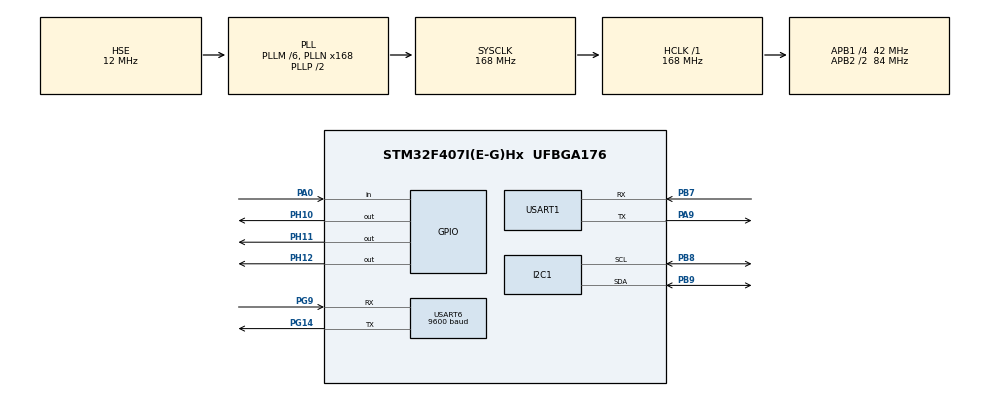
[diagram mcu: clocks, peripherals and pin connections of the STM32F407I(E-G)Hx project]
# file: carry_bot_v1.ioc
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Dma.I2C1_RX.4.Direction=DMA_PERIPH_TO_MEMORY
Dma.I2C1_RX.4.FIFOMode=DMA_FIFOMODE_DISABLE
Dma.I2C1_RX.4.Instance=DMA1_Stream0
Dma.I2C1_RX.4.MemDataAlignment=DMA_MDATAALIGN_BYTE
Dma.I2C1_RX.4.MemInc=DMA_MINC_ENABLE
Dma.I2C1_RX.4.Mode=DMA_NORMAL
Dma.I2C1_RX.4.PeriphDataAlignment=DMA_PDATAALIGN_BYTE
Dma.I2C1_RX.4.PeriphInc=DMA_PINC_DISABLE
Dma.I2C1_RX.4.Priority=DMA_PRIORITY_LOW
Dma.I2C1_TX.5.Direction=DMA_MEMORY_TO_PERIPH
Dma.I2C1_TX.5.FIFOMode=DMA_FIFOMODE_DISABLE
Dma.I2C1_TX.5.Instance=DMA1_Stream6
Dma.I2C1_TX.5.MemDataAlignment=DMA_MDATAALIGN_BYTE
Dma.I2C1_TX.5.MemInc=DMA_MINC_ENABLE
Dma.I2C1_TX.5.Mode=DMA_NORMAL
Dma.I2C1_TX.5.PeriphDataAlignment=DMA_PDATAALIGN_BYTE
Dma.I2C1_TX.5.PeriphInc=DMA_PINC_DISABLE
Dma.I2C1_TX.5.Priority=DMA_PRIORITY_LOW
Dma.Request0=USART6_RX
Dma.Request1=USART6_TX
Dma.Request2=USART1_RX
Dma.Request3=USART1_TX
Dma.Request4=I2C1_RX
Dma.Request5=I2C1_TX
Dma.USART1_RX.2.Direction=DMA_PERIPH_TO_MEMORY
Dma.USART1_RX.2.FIFOMode=DMA_FIFOMODE_DISABLE
Dma.USART1_RX.2.Instance=DMA2_Stream2
Dma.USART1_RX.2.MemDataAlignment=DMA_MDATAALIGN_BYTE
Dma.USART1_RX.2.MemInc=DMA_MINC_ENABLE
Dma.USART1_RX.2.Mode=DMA_NORMAL
Dma.USART1_RX.2.PeriphDataAlignment=DMA_PDATAALIGN_BYTE
Dma.USART1_RX.2.PeriphInc=DMA_PINC_DISABLE
Dma.USART1_RX.2.Priority=DMA_PRIORITY_LOW
Dma.USART1_TX.3.Direction=DMA_MEMORY_TO_PERIPH
Dma.USART1_TX.3.FIFOMode=DMA_FIFOMODE_DISABLE
Dma.USART1_TX.3.Instance=DMA2_Stream7
Dma.USART1_TX.3.MemDataAlignment=DMA_MDATAALIGN_BYTE
Dma.USART1_TX.3.MemInc=DMA_MINC_ENABLE
Dma.USART1_TX.3.Mode=DMA_NORMAL
Dma.USART1_TX.3.PeriphDataAlignment=DMA_PDATAALIGN_BYTE
Dma.USART1_TX.3.PeriphInc=DMA_PINC_DISABLE
Dma.USART1_TX.3.Priority=DMA_PRIORITY_LOW
Dma.USART6_RX.0.Direction=DMA_PERIPH_TO_MEMORY
Dma.USART6_RX.0.FIFOMode=DMA_FIFOMODE_DISABLE
Dma.USART6_RX.0.Instance=DMA2_Stream1
Dma.USART6_RX.0.MemDataAlignment=DMA_MDATAALIGN_BYTE
Dma.USART6_RX.0.MemInc=DMA_MINC_ENABLE
Dma.USART6_RX.0.Mode=DMA_NORMAL
Dma.USART6_RX.0.PeriphDataAlignment=DMA_PDATAALIGN_BYTE
Dma.USART6_RX.0.PeriphInc=DMA_PINC_DISABLE
Dma.USART6_RX.0.Priority=DMA_PRIORITY_LOW
Dma.USART6_TX.1.Direction=DMA_MEMORY_TO_PERIPH
Dma.USART6_TX.1.FIFOMode=DMA_FIFOMODE_DISABLE
Dma.USART6_TX.1.Instance=DMA2_Stream6
Dma.USART6_TX.1.MemDataAlignment=DMA_MDATAALIGN_BYTE
Dma.USART6_TX.1.MemInc=DMA_MINC_ENABLE
Dma.USART6_TX.1.Mode=DMA_NORMAL
Dma.USART6_TX.1.PeriphDataAlignment=DMA_PDATAALIGN_BYTE
Dma.USART6_TX.1.PeriphInc=DMA_PINC_DISABLE
Dma.USART6_TX.1.Priority=DMA_PRIORITY_LOW
FREERTOS.Tasks01=defaultTask,24,128,StartDefaultTask,Default,NULL,Dynamic,NULL,NULL
I2C1.I2C_Mode=I2C_Fast
Mcu.Family=STM32F4
Mcu.Name=STM32F407I(E-G)Hx
Mcu.Package=UFBGA176
NVIC.DMA1_Stream0_IRQn=true\:5\:0\:false\:false\:true\:true\:false\:true\:true
NVIC.DMA1_Stream6_IRQn=true\:5\:0\:false\:false\:true\:true\:false\:true\:true
NVIC.DMA2_Stream1_IRQn=true\:5\:0\:false\:false\:true\:true\:false\:true\:true
NVIC.DMA2_Stream2_IRQn=true\:5\:0\:false\:false\:true\:true\:false\:true\:true
NVIC.DMA2_Stream6_IRQn=true\:5\:0\:false\:false\:true\:true\:false\:true\:true
NVIC.DMA2_Stream7_IRQn=true\:5\:0\:false\:false\:true\:true\:false\:true\:true
NVIC.I2C1_EV_IRQn=true\:5\:0\:false\:false\:true\:true\:true\:true\:true
NVIC.PriorityGroup=NVIC_PRIORITYGROUP_4
NVIC.TIM7_IRQn=true\:15\:0\:false\:false\:true\:false\:false\:true\:true
NVIC.TimeBase=TIM7_IRQn
NVIC.TimeBaseIP=TIM7
NVIC.USART1_IRQn=true\:5\:0\:false\:false\:true\:true\:false\:true\:true
NVIC.USART6_IRQn=true\:5\:0\:false\:false\:true\:true\:false\:true\:true
PA13.Mode=Serial_Wire
PA13.Signal=SYS_JTMS-SWDIO
PA14.Mode=Serial_Wire
PA14.Signal=SYS_JTCK-SWCLK
PA9.Mode=Asynchronous
PA9.Signal=USART1_TX
PB7.Mode=Asynchronous
PB7.Signal=USART1_RX
PB8.Mode=I2C
PB8.Signal=I2C1_SCL
PB9.Mode=I2C
PB9.Signal=I2C1_SDA
PG14.Mode=Asynchronous
PG14.Signal=USART6_TX
PG9.Mode=Asynchronous
PG9.Signal=USART6_RX
PH0-OSC_IN.Mode=HSE-External-Oscillator
PH0-OSC_IN.Signal=RCC_OSC_IN
PH1-OSC_OUT.Mode=HSE-External-Oscillator
PH1-OSC_OUT.Signal=RCC_OSC_OUT
PH10.GPIO_PuPd=GPIO_PULLUP
PH10.GPIO_Speed=GPIO_SPEED_FREQ_LOW
PH10.Signal=GPIO_Output
PH11.GPIO_PuPd=GPIO_PULLUP
PH11.GPIO_Speed=GPIO_SPEED_FREQ_LOW
PH11.Signal=GPIO_Output
PH12.GPIO_PuPd=GPIO_PULLUP
PH12.GPIO_Speed=GPIO_SPEED_FREQ_LOW
PH12.Signal=GPIO_Output
PA0-WKUP.GPIO_PuPd=GPIO_PULLUP
PA0-WKUP.Signal=GPIO_Input
ProjectManager.HeapSize=0x200
ProjectManager.StackSize=0x400
ProjectManager.TargetToolchain=CMake
RCC.48MHZClocksFreq_Value=48000000
RCC.AHBFreq_Value=168000000
RCC.APB1CLKDivider=RCC_HCLK_DIV4
RCC.APB1Freq_Value=42000000
RCC.APB1TimFreq_Value=84000000
RCC.APB2CLKDivider=RCC_HCLK_DIV2
RCC.APB2Freq_Value=84000000
RCC.APB2TimFreq_Value=168000000
RCC.CortexFreq_Value=168000000
RCC.HCLKFreq_Value=168000000
RCC.HSE_VALUE=12000000
RCC.HSI_VALUE=16000000
RCC.LSE_VALUE=32768
RCC.PLLM=6
RCC.PLLN=168
RCC.PLLQ=7
RCC.PLLSourceVirtual=RCC_PLLSOURCE_HSE
RCC.SYSCLKFreq_VALUE=168000000
RCC.SYSCLKSource=RCC_SYSCLKSOURCE_PLLCLK
RCC.VCOOutputFreq_Value=336000000
USART1.VirtualMode=VM_ASYNC
USART6.BaudRate=9600
USART6.VirtualMode=VM_ASYNC
VP_FREERTOS_VS_CMSIS_V2.Mode=CMSIS_V2
VP_SYS_VS_tim7.Mode=TIM7
board=custom

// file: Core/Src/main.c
/* USER CODE BEGIN Header */
/**
  ******************************************************************************
  * @file           : main.c
  * @brief          : Main program body
  ******************************************************************************
  * @attention
  *
  * Copyright (c) 2026 STMicroelectronics.
  * All rights reserved.
  *
  * This software is licensed under terms that can be found in the LICENSE file
  * in the root directory of this software component.
  * If no LICENSE file comes with this software, it is provided AS-IS.
  *
  ******************************************************************************
  */
/* USER CODE END Header */
#include "main.h"
#include "cmsis_os.h"
#include "dma.h"
#include "i2c.h"
#include "usart.h"
#include "gpio.h"

void SystemClock_Config(void);
void MX_FREERTOS_Init(void);

int main(void)
{

  /* MCU Configuration--------------------------------------------------------*/

  /* Reset of all peripherals, Initializes the Flash interface and the Systick. */
  HAL_Init();

  /* Configure the system clock */
  SystemClock_Config();

  /* Initialize all configured peripherals */
  MX_GPIO_Init();
  MX_DMA_Init();
  MX_USART6_UART_Init();
  MX_USART1_UART_Init();
  MX_I2C1_Init();

  /* Init scheduler */
  osKernelInitialize();  /* Call init function for freertos objects (in cmsis_os2.c) */
  MX_FREERTOS_Init();

  /* Start scheduler */
  osKernelStart();

  /* We should never get here as control is now taken by the scheduler */

  /* Infinite loop */
  while (1)
  {

  }
}

void SystemClock_Config(void)
{
  RCC_OscInitTypeDef RCC_OscInitStruct = {0};
  RCC_ClkInitTypeDef RCC_ClkInitStruct = {0};

  /** Configure the main internal regulator output voltage
  */
  __HAL_RCC_PWR_CLK_ENABLE();
  __HAL_PWR_VOLTAGESCALING_CONFIG(PWR_REGULATOR_VOLTAGE_SCALE1);

  /** Initializes the RCC Oscillators according to the specified parameters
  * in the RCC_OscInitTypeDef structure.
  */
  /* DJI RoboMaster Development Board Type-C: 12 MHz HSE crystal on PH0/PH1.
   * 24 MHz is not the board clock — driving the PLL from HSI hides a dead HSE.
   * 12 MHz / PLLM(6) = 2 MHz VCO in, x PLLN(168) = 336 MHz VCO,
   * / PLLP(2) = 168 MHz SYSCLK, / PLLQ(7) = 48 MHz (USB/SDIO). */
  RCC_OscInitStruct.OscillatorType = RCC_OSCILLATORTYPE_HSE;
  RCC_OscInitStruct.HSEState = RCC_HSE_ON;
  RCC_OscInitStruct.PLL.PLLState = RCC_PLL_ON;
  RCC_OscInitStruct.PLL.PLLSource = RCC_PLLSOURCE_HSE;
  RCC_OscInitStruct.PLL.PLLM = 6;
  RCC_OscInitStruct.PLL.PLLN = 168;
  RCC_OscInitStruct.PLL.PLLP = RCC_PLLP_DIV2;
  RCC_OscInitStruct.PLL.PLLQ = 7;
  if (HAL_RCC_OscConfig(&RCC_OscInitStruct) != HAL_OK)
  {
    Error_Handler();
  }

  /** Initializes the CPU, AHB and APB buses clocks
  */
  RCC_ClkInitStruct.ClockType = RCC_CLOCKTYPE_HCLK|RCC_CLOCKTYPE_SYSCLK
                              |RCC_CLOCKTYPE_PCLK1|RCC_CLOCKTYPE_PCLK2;
  RCC_ClkInitStruct.SYSCLKSource = RCC_SYSCLKSOURCE_PLLCLK;
  RCC_ClkInitStruct.AHBCLKDivider = RCC_SYSCLK_DIV1;
  RCC_ClkInitStruct.APB1CLKDivider = RCC_HCLK_DIV4;
  RCC_ClkInitStruct.APB2CLKDivider = RCC_HCLK_DIV2;

  if (HAL_RCC_ClockConfig(&RCC_ClkInitStruct, FLASH_LATENCY_5) != HAL_OK)
  {
    Error_Handler();
  }
}

void HAL_TIM_PeriodElapsedCallback(TIM_HandleTypeDef *htim)
{
  if (htim->Instance == TIM7)
  {
    HAL_IncTick();
  }
}

void Error_Handler(void)
{
  __disable_irq();
  while (1)
  {
  }
}

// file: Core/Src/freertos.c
/* USER CODE BEGIN Header */
/**
  ******************************************************************************
  * File Name          : freertos.c
  * Description        : Code for freertos applications
  ******************************************************************************
  * @attention
  *
  * Copyright (c) 2026 STMicroelectronics.
  * All rights reserved.
  *
  * This software is licensed under terms that can be found in the LICENSE file
  * in the root directory of this software component.
  * If no LICENSE file comes with this software, it is provided AS-IS.
  *
  ******************************************************************************
  */
/* USER CODE END Header */

#include "FreeRTOS.h"
#include "task.h"
#include "main.h"
#include "cmsis_os.h"

/* USER CODE BEGIN Includes */
#include "usart.h"
#include <string.h>
/* USER CODE END Includes */

/* USER CODE BEGIN Variables */
/* Definitions for defaultTask */
osThreadId_t defaultTaskHandle;
const osThreadAttr_t defaultTask_attributes = {
  .name = "defaultTask",
  .stack_size = 128 * 4,
  .priority = (osPriority_t) osPriorityNormal,
};

void StartDefaultTask(void *argument);

void MX_FREERTOS_Init(void); /* (MISRA C 2004 rule 8.1) */

void MX_FREERTOS_Init(void) {

  /* Create the thread(s) */
  /* creation of defaultTask */
  defaultTaskHandle = osThreadNew(StartDefaultTask, NULL, &defaultTask_attributes);

  /* USER CODE BEGIN RTOS_THREADS */
  /* hello-tx diagnostic: do not start Link/ZDT/Servo */
/* USER CODE END RTOS_THREADS */

}

void StartDefaultTask(void *argument)
{
  /* USER CODE BEGIN StartDefaultTask */
  /* Shell UART2 = USART1 @115200 TX (PA9) */
  static const char msg[] = "hello\r\n";
  for(;;)
  {
    (void)HAL_UART_Transmit(&huart1, (uint8_t *)msg, (uint16_t)(sizeof(msg) - 1U), 100);
    osDelay(500);
  }
  /* USER CODE END StartDefaultTask */
}
